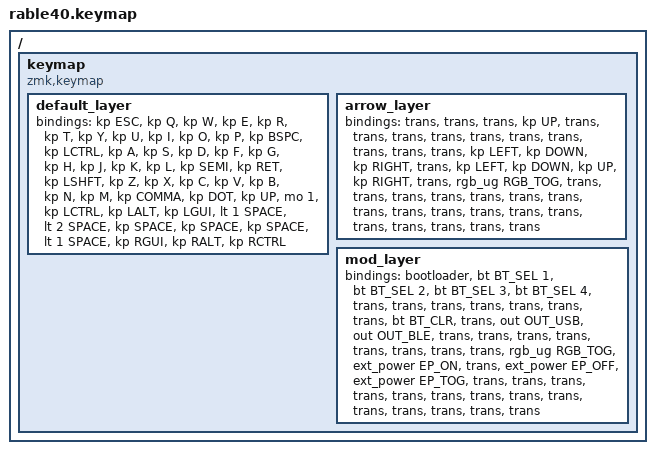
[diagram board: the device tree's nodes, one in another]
/*
 * Copyright (c) 2021 Nick Winans
 *
 * SPDX-License-Identifier: MIT
 */

#include <behaviors.dtsi>
#include <dt-bindings/zmk/keys.h>
#include <dt-bindings/zmk/rgb.h>
#include <dt-bindings/zmk/bt.h>
#include <dt-bindings/zmk/outputs.h>
#include <dt-bindings/zmk/ext_power.h>

/ {
  keymap {
    compatible = "zmk,keymap";
    
    default_layer {
      bindings = <
        &kp ESC    &kp Q    &kp W    &kp E    &kp R    &kp T    &kp Y    &kp U    &kp I      &kp O    &kp P     &kp BSPC        
        &kp LCTRL   &kp A    &kp S  &kp D    &kp F    &kp G    &kp H    &kp J    &kp K      &kp L    &kp SEMI  &kp RET                   
        &kp LSHFT  &kp Z    &kp X    &kp C    &kp V    &kp B    &kp N    &kp M    &kp COMMA  &kp DOT  &kp UP   &mo 1   
        &kp LCTRL  &kp LALT &kp LGUI   &lt 1 SPACE   &lt 2 SPACE   &kp SPACE &kp SPACE  &kp SPACE &lt 1 SPACE &kp RGUI    &kp RALT &kp RCTRL
      >;
    };

    arrow_layer {
      bindings = <
        &trans   &trans   &trans    &kp UP   &trans    &trans   &trans    &trans   &trans    &trans   &trans    &trans      
        &trans  &trans   &kp LEFT   &kp DOWN   &kp RIGHT  &trans   &kp LEFT  &kp DOWN &kp UP   &kp RIGHT &trans   &rgb_ug RGB_TOG               
        &trans  &trans &trans   &trans    &trans   &trans    &trans   &trans    &trans   &trans    &trans   &trans            &trans     
               &trans   &trans                                   &trans                                        &trans      &trans     
      >;
    };
    
    mod_layer {
      bindings = <
        &bootloader  &bt BT_SEL 1  &bt BT_SEL 2   &bt BT_SEL 3  &bt BT_SEL 4   &trans   &trans    &trans   &trans    &trans   &trans    &trans   &bt BT_CLR       
        &trans  &out OUT_USB   &out OUT_BLE    &trans   &trans    &trans   &trans    &trans   &trans    &trans   &trans   &rgb_ug RGB_TOG             
        &ext_power EP_ON  &trans &ext_power EP_OFF   &ext_power EP_TOG    &trans   &trans    &trans   &trans    &trans   &trans    &trans   &trans     &trans           
               &trans   &trans                                   &trans                                         &trans   &trans     
      >;
    };
    
  };
};
